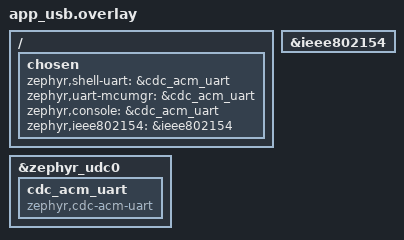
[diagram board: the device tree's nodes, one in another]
/*
 * Copyright (c) 2022 Nordic Semiconductor ASA
 *
 * SPDX-License-Identifier: LicenseRef-Nordic-5-Clause
 */

 &zephyr_udc0 {
	cdc_acm_uart: cdc_acm_uart {
		compatible = "zephyr,cdc-acm-uart";
	};
};

&ieee802154 {
	status = "okay";
};

 / {
	chosen {
		zephyr,shell-uart = &cdc_acm_uart;
		zephyr,uart-mcumgr = &cdc_acm_uart;
		zephyr,console = &cdc_acm_uart;
        zephyr,ieee802154 = &ieee802154;
	};
};
